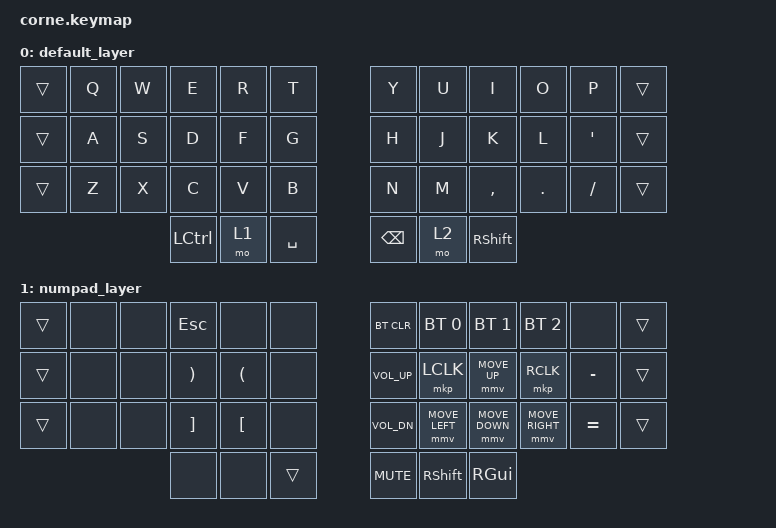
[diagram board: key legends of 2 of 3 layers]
#include <behaviors.dtsi>
#include <dt-bindings/zmk/keys.h>
#include <dt-bindings/zmk/bt.h>
#include <dt-bindings/zmk/mouse.h>
&mt {
    tapping-term-ms = <300>;
};
&mmv {
    time-to-max-speed-ms = <50>;
};
/ {
    behaviors {
        td_lpar: tap_dance_left_paranthesis {
            compatible = "zmk,behavior-tap-dance";
            label = "TAP_DANCE_LEFT_PARANTHESIS";
            #binding-cells = <0>;
            tapping-term-ms = <300>;
            bindings = <&kp LPAR>, <&kp LBKT>, <&kp LBRC>;
        };
        td_rpar: tap_dance_right_paranthesis {
            compatible = "zmk,behavior-tap-dance";
            label = "TAP_DANCE_RIGHT_PARANTHESIS";
            #binding-cells = <0>;
            tapping-term-ms = <300>;
            bindings = <&kp RPAR>, <&kp RBKT>, <&kp RBRC>;
        };
    };
    combos {
        compatible = "zmk,combos";
        combo_enter_1 {
            timeout-ms = <50>;
            key-positions = <15 16>;
            bindings = <&kp ENTER>;
        };
        combo_enter_2 {
            timeout-ms = <50>;
            key-positions = <19 20>;
            bindings = <&kp ENTER>;
        };
        combo_tab {
            timeout-ms = <50>;
            key-positions = <14 15>;
            bindings = <&kp TAB>;
        };
        combo_gui {
            timeout-ms = <50>;
            key-positions = <37 40>;
            bindings = <&kp LGUI>;
        };
    };
        keymap {
                compatible = "zmk,keymap";
                default_layer {
                        bindings = <
      // ╭─────────────┬─────────────┬─────────────┬─────────────┬─────────────╮   ╭─────────────┬─────────────┬─────────────┬─────────────┬─────────────╮
   &trans    &kp Q          &kp W         &kp E         &kp R        &kp T             &kp Y          &kp U        &kp I          &kp O       &kp P        &trans
      // ├─────────────┼─────────────┼─────────────┼─────────────┼─────────────┤   ├─────────────┼─────────────┼─────────────┼─────────────┼─────────────┤
   &trans    &kp A          &kp S         &kp D         &kp F        &kp G             &kp H          &kp J        &kp K          &kp L       &kp SQT      &trans
      // ├─────────────┼─────────────┼─────────────┼─────────────┼─────────────┤   ├─────────────┼─────────────┼─────────────┼─────────────┼─────────────┤
   &trans    &kp Z          &kp X         &kp C         &kp V        &kp B             &kp N          &kp M        &kp COMMA      &kp DOT     &kp FSLH     &trans
      // ╰─────────────┴─────────────┼─────────────┼─────────────┼─────────────┤   ├─────────────┼─────────────┼─────────────┼─────────────┴─────────────╯
                                          &kp LCTRL     &mo 1      &kp SPACE           &kp BSPC       &mo 2        &kp RSHFT
      //                             ╰─────────────┴─────────────┴─────────────╯   ╰─────────────┴─────────────┴─────────────╯
                        >; 
                };
                numpad_layer {
                        bindings = <
      // ╭─────────────┬─────────────┬─────────────┬─────────────┬─────────────╮   ╭─────────────┬─────────────┬─────────────┬─────────────┬─────────────╮
   &trans    &none        &none          &kp ESC       &none         &none          &bt BT_CLR     &bt BT_SEL 0  &bt BT_SEL 1   &bt BT_SEL 2    &none       &trans
      // ├─────────────┼─────────────┼─────────────┼─────────────┼─────────────┤   ├─────────────┼─────────────┼─────────────┼─────────────┼─────────────┤
   &trans    &none        &none          &kp RPAR      &kp LPAR      &none          &kp C_VOL_UP     &mkp LCLK   &mmv MOVE_UP   &mkp RCLK     &kp MINUS    &trans
      // ├─────────────┼─────────────┼─────────────┼─────────────┼─────────────┤   ├─────────────┼─────────────┼─────────────┼─────────────┼─────────────┤
   &trans    &none        &none          &kp RBKT      &kp LBKT      &none          &kp C_VOL_DN  &mmv MOVE_LEFT &mmv MOVE_DOWN &mmv MOVE_RIGHT &kp EQUAL    &trans
      // ╰─────────────┴─────────────┼─────────────┼─────────────┼─────────────┤   ├─────────────┼─────────────┼─────────────┼─────────────┴─────────────╯
                                          &none        &none         &trans         &kp C_MUTE      &kp RSHFT      &kp RGUI      
      //                             ╰─────────────┴─────────────┴─────────────╯   ╰─────────────┴─────────────┴─────────────╯
                        >;
                };
                nav_symbol_layer {
                        bindings = <
      // ╭─────────────┬─────────────┬─────────────┬─────────────┬─────────────╮   ╭─────────────┬─────────────┬─────────────┬─────────────┬─────────────╮
   &trans    &kp N1       &kp N2        &kp N3        &kp N4        &kp N5            &kp N6         &kp N7        &kp N8       &kp N9          &kp N0        &trans
      // ├─────────────┼─────────────┼─────────────┼─────────────┼─────────────┤   ├─────────────┼─────────────┼─────────────┼─────────────┼─────────────┤
   &trans    &none        &kp SEMI      &none      &mwh SCROLL_UP   &none             &kp PG_UP     &kp HOME      &kp UP        &kp END      &none         &trans
      // ├─────────────┼─────────────┼─────────────┼─────────────┼─────────────┤   ├─────────────┼─────────────┼─────────────┼─────────────┼─────────────┤
   &trans    &none        &none        &kp COLON   &mwh SCROLL_DOWN &none             &kp BSLH          &kp PG_DN     &kp LEFT      &kp DOWN      &kp RIGHT    &none         &trans
      // ╰─────────────┴─────────────┼─────────────┼─────────────┼─────────────┤   ├─────────────┼─────────────┼─────────────┼─────────────┴─────────────╯
                                         &none        &kp LSHFT     &none             &none         &none         &none      
      //                             ╰─────────────┴─────────────┴─────────────╯   ╰─────────────┴─────────────┴─────────────╯
                        >;
                };
        };
};
